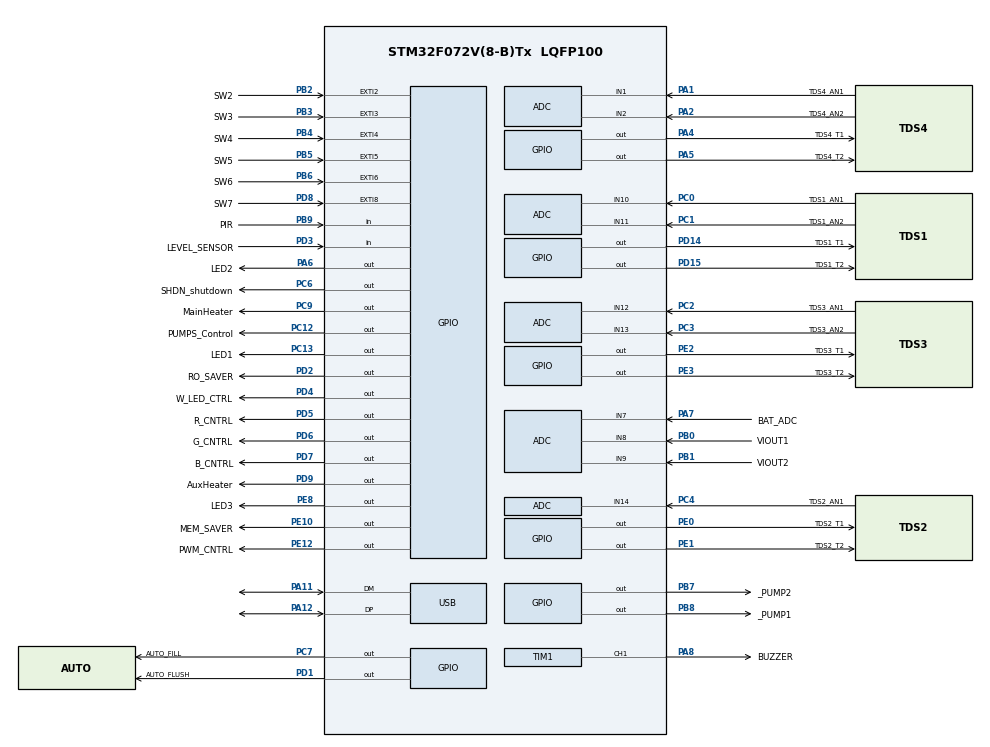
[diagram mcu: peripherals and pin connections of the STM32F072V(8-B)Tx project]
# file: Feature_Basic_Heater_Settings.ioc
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ADC.ContinuousConvMode=ENABLE
Mcu.Family=STM32F0
Mcu.Name=STM32F072V(8-B)Tx
Mcu.Package=LQFP100
NVIC.EXTI2_3_IRQn=true\:0\:0\:false\:false\:true\:true\:true\:true
NVIC.EXTI4_15_IRQn=true\:0\:0\:false\:false\:true\:true\:true\:true
NVIC.TIM1_BRK_UP_TRG_COM_IRQn=true\:0\:0\:false\:false\:true\:true\:true\:true
NVIC.TIM1_CC_IRQn=true\:0\:0\:false\:false\:true\:true\:true\:true
NVIC.TIM6_DAC_IRQn=true\:0\:0\:false\:false\:true\:true\:true\:true
NVIC.USB_IRQn=true\:0\:0\:false\:false\:true\:false\:true\:true
PA1.GPIO_Label=TDS4_AN1
PA1.Mode=IN1
PA1.Signal=ADC_IN1
PA11.Mode=Device
PA11.Signal=USB_DM
PA12.Mode=Device
PA12.Signal=USB_DP
PA2.GPIO_Label=TDS4_AN2
PA2.Mode=IN2
PA2.Signal=ADC_IN2
PA4.GPIO_Label=TDS4_T1
PA4.Signal=GPIO_Output
PA5.GPIO_Label=TDS4_T2
PA5.Signal=GPIO_Output
PA6.GPIO_Label=LED2
PA6.Signal=GPIO_Output
PA7.GPIO_Label=BAT_ADC
PA7.Mode=IN7
PA7.Signal=ADC_IN7
PA8.GPIO_Label=BUZZER
PA8.Signal=S_TIM1_CH1
PB0.GPIO_Label=VIOUT1
PB0.Mode=IN8
PB0.Signal=ADC_IN8
PB1.GPIO_Label=VIOUT2
PB1.Mode=IN9
PB1.Signal=ADC_IN9
PB2.GPIO_Label=SW2
PB2.GPIO_ModeDefaultEXTI=GPIO_MODE_IT_FALLING
PB2.Signal=GPXTI2
PB3.GPIO_Label=SW3
PB3.GPIO_ModeDefaultEXTI=GPIO_MODE_IT_FALLING
PB3.Signal=GPXTI3
PB4.GPIO_Label=SW4
PB4.GPIO_ModeDefaultEXTI=GPIO_MODE_IT_FALLING
PB4.Signal=GPXTI4
PB5.GPIO_Label=SW5
PB5.GPIO_ModeDefaultEXTI=GPIO_MODE_IT_FALLING
PB5.Signal=GPXTI5
PB6.GPIO_Label=SW6
PB6.GPIO_ModeDefaultEXTI=GPIO_MODE_IT_FALLING
PB6.Signal=GPXTI6
PB7.GPIO_Label=_PUMP2
PB7.Signal=GPIO_Output
PB8.GPIO_Label=_PUMP1
PB8.Signal=GPIO_Output
PB9.GPIO_Label=PIR
PB9.Signal=GPIO_Input
PC0.GPIO_Label=TDS1_AN1
PC0.Mode=IN10
PC0.Signal=ADC_IN10
PC1.GPIO_Label=TDS1_AN2
PC1.Mode=IN11
PC1.Signal=ADC_IN11
PC12.GPIO_Label=PUMPS_Control
PC12.Signal=GPIO_Output
PC13.GPIO_Label=LED1
PC13.Signal=GPIO_Output
PC2.GPIO_Label=TDS3_AN1
PC2.Mode=IN12
PC2.Signal=ADC_IN12
PC3.GPIO_Label=TDS3_AN2
PC3.Mode=IN13
PC3.Signal=ADC_IN13
PC4.GPIO_Label=TDS2_AN1
PC4.Mode=IN14
PC4.Signal=ADC_IN14
PC5.GPIO_Label=TDS2_AN2
PC5.Signal=ADC_IN15
PC6.GPIO_Label=SHDN_shutdown
PC6.Signal=GPIO_Output
PC7.GPIO_Label=AUTO_FILL
PC7.Signal=GPIO_Output
PC9.GPIO_Label=MainHeater
PC9.Signal=GPIO_Output
PD1.GPIO_Label=AUTO_FLUSH
PD1.Signal=GPIO_Output
PD14.GPIO_Label=TDS1_T1
PD14.Signal=GPIO_Output
PD15.GPIO_Label=TDS1_T2
PD15.Signal=GPIO_Output
PD2.GPIO_Label=RO_SAVER
PD2.Signal=GPIO_Output
PD3.GPIO_Label=LEVEL_SENSOR
PD3.GPIO_PuPd=GPIO_PULLUP
PD3.Signal=GPIO_Input
PD4.GPIO_Label=W_LED_CTRL
PD4.Signal=GPIO_Output
PD5.GPIO_Label=R_CNTRL
PD5.Signal=GPIO_Output
PD6.GPIO_Label=G_CNTRL
PD6.Signal=GPIO_Output
PD7.GPIO_Label=B_CNTRL
PD7.Signal=GPIO_Output
PD8.GPIO_Label=SW7
PD8.GPIO_ModeDefaultEXTI=GPIO_MODE_IT_FALLING
PD8.Signal=GPXTI8
PD9.GPIO_Label=AuxHeater
PD9.Signal=GPIO_Output
PE0.GPIO_Label=TDS2_T1
PE0.Signal=GPIO_Output
PE1.GPIO_Label=TDS2_T2
PE1.Signal=GPIO_Output
PE10.GPIO_Label=MEM_SAVER
PE10.Signal=GPIO_Output
PE12.GPIO_Label=PWM_CNTRL
PE12.Signal=GPIO_Output
PE2.GPIO_Label=TDS3_T1
PE2.Signal=GPIO_Output
PE3.GPIO_Label=TDS3_T2
PE3.Signal=GPIO_Output
PE8.GPIO_Label=LED3
PE8.Signal=GPIO_Output
PF0-OSC_IN.Mode=HSE-External-Oscillator
PF0-OSC_IN.Signal=RCC_OSC_IN
PF1-OSC_OUT.Mode=HSE-External-Oscillator
PF1-OSC_OUT.Signal=RCC_OSC_OUT
ProjectManager.HeapSize=0x200
ProjectManager.StackSize=0x400
ProjectManager.TargetToolchain=STM32CubeIDE
RCC.AHBFreq_Value=48000000
RCC.APB1Freq_Value=48000000
RCC.APB1TimFreq_Value=48000000
RCC.HCLKFreq_Value=48000000
RCC.SYSCLKFreq_VALUE=48000000
RCC.SYSCLKSource=RCC_SYSCLKSOURCE_HSI48
SH.S_TIM1_CH1.0=TIM1_CH1,PWM Generation1 CH1
TIM1.Channel-PWM\ Generation1\ CH1=TIM_CHANNEL_1
TIM1.Channel-PWM\ Generation2\ No\ Output=TIM_CHANNEL_2
TIM1.Channel-PWM\ Generation3\ No\ Output=TIM_CHANNEL_3
TIM1.Channel-PWM\ Generation4\ No\ Output=TIM_CHANNEL_4
TIM1.Period=1000-1
TIM1.Prescaler=48-1
TIM1.Pulse-PWM\ Generation1\ CH1=499
TIM6.Period=100
TIM6.Prescaler=48000
USB_DEVICE.CLASS_NAME_FS=CDC
USB_DEVICE.VirtualMode=Cdc
USB_DEVICE.VirtualModeFS=Cdc_FS
VP_TIM1_VS_ClockSourceINT.Mode=Internal
VP_TIM1_VS_no_output2.Mode=PWM Generation2 No Output
VP_TIM1_VS_no_output3.Mode=PWM Generation3 No Output
VP_TIM1_VS_no_output4.Mode=PWM Generation4 No Output
VP_TIM6_VS_ClockSourceINT.Mode=Enable_Timer
VP_USB_DEVICE_VS_USB_DEVICE_CDC_FS.Mode=CDC_FS
board=custom

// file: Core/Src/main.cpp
/* USER CODE BEGIN Header */
/**
  ******************************************************************************
  * @file           : main.c
  * @brief          : Main program body
  ******************************************************************************
  * @attention
  *
  * Copyright (c) 2024 STMicroelectronics.
  * All rights reserved.
  *
  * This software is licensed under terms that can be found in the LICENSE file
  * in the root directory of this software component.
  * If no LICENSE file comes with this software, it is provided AS-IS.
  *
  ******************************************************************************
  */
/* USER CODE END Header */
#include <mainApp.hpp>
#include "main.h"
#include "usb_device.h"
#include "_DEBUG_.h"

/* USER CODE BEGIN PD */
#define TIME 5*1000
/* USER CODE END PD */

TIM_HandleTypeDef htim1;
TIM_HandleTypeDef htim6;
ADC_HandleTypeDef hadc;

/* USER CODE BEGIN PV */
MainApp app;
/* USER CODE END PV */

extern "C" void SystemClock_Config(void);
static void MX_GPIO_Init(void);
static void MX_ADC_Init(void);
static void MX_TIM1_Init(void);
static void MX_TIM6_Init(void);
//static void MX_TIM17_Init(void);

int main(void)
{

  /* MCU Configuration--------------------------------------------------------*/

  /* Reset of all peripherals, Initializes the Flash interface and the Systick. */
  HAL_Init();

  /* Configure the system clock */
  SystemClock_Config();

  /* USER CODE BEGIN 2 */

  /* Initialize all configured peripherals */
  MX_GPIO_Init();
  MX_USB_DEVICE_Init();
  MX_ADC_Init();
  MX_TIM1_Init();
  MX_TIM6_Init();
//  MX_TIM17_Init();

  app.setup();
  /* USER CODE END 2 */

  /* Infinite loop */
  while (1)
  {

    /* USER CODE BEGIN 3 */
	  app.loop();
  }
  /* USER CODE END 3 */
}

extern "C" void SystemClock_Config(void)
{
  RCC_OscInitTypeDef RCC_OscInitStruct = {0};
  RCC_ClkInitTypeDef RCC_ClkInitStruct = {0};
  RCC_PeriphCLKInitTypeDef PeriphClkInit = {0};

  /** Initializes the RCC Oscillators according to the specified parameters
  * in the RCC_OscInitTypeDef structure.
  */
  RCC_OscInitStruct.OscillatorType = RCC_OSCILLATORTYPE_HSI14|RCC_OSCILLATORTYPE_HSI48;
  RCC_OscInitStruct.HSI48State = RCC_HSI48_ON;
  RCC_OscInitStruct.HSI14State = RCC_HSI14_ON;
  RCC_OscInitStruct.HSI14CalibrationValue = 16;
  RCC_OscInitStruct.PLL.PLLState = RCC_PLL_NONE;
  if (HAL_RCC_OscConfig(&RCC_OscInitStruct) != HAL_OK)
  {
    Error_Handler();
  }

  /** Initializes the CPU, AHB and APB buses clocks
  */
  RCC_ClkInitStruct.ClockType = RCC_CLOCKTYPE_HCLK|RCC_CLOCKTYPE_SYSCLK
                              |RCC_CLOCKTYPE_PCLK1;
  RCC_ClkInitStruct.SYSCLKSource = RCC_SYSCLKSOURCE_HSI48;
  RCC_ClkInitStruct.AHBCLKDivider = RCC_SYSCLK_DIV1;
  RCC_ClkInitStruct.APB1CLKDivider = RCC_HCLK_DIV1;

  if (HAL_RCC_ClockConfig(&RCC_ClkInitStruct, FLASH_LATENCY_1) != HAL_OK)
  {
    Error_Handler();
  }
  PeriphClkInit.PeriphClockSelection = RCC_PERIPHCLK_USB;
  PeriphClkInit.UsbClockSelection = RCC_USBCLKSOURCE_HSI48;

  if (HAL_RCCEx_PeriphCLKConfig(&PeriphClkInit) != HAL_OK)
  {
    Error_Handler();
  }
}

static void MX_ADC_Init(void)
{

  ADC_ChannelConfTypeDef sConfig = {0};

  /** Configure the global features of the ADC (Clock, Resolution, Data Alignment and number of conversion)
  */
  hadc.Instance = ADC1;
  hadc.Init.ClockPrescaler = ADC_CLOCK_ASYNC_DIV1;
  hadc.Init.Resolution = ADC_RESOLUTION_12B;
  hadc.Init.DataAlign = ADC_DATAALIGN_RIGHT;
  hadc.Init.ScanConvMode = ADC_SCAN_DIRECTION_FORWARD;
  hadc.Init.EOCSelection = ADC_EOC_SINGLE_CONV;
  hadc.Init.LowPowerAutoWait = DISABLE;
  hadc.Init.LowPowerAutoPowerOff = DISABLE;
  hadc.Init.ContinuousConvMode = ENABLE;
  hadc.Init.DiscontinuousConvMode = DISABLE;
  hadc.Init.ExternalTrigConv = ADC_SOFTWARE_START;
  hadc.Init.ExternalTrigConvEdge = ADC_EXTERNALTRIGCONVEDGE_NONE;
  hadc.Init.DMAContinuousRequests = DISABLE;
  hadc.Init.Overrun = ADC_OVR_DATA_PRESERVED;
  if (HAL_ADC_Init(&hadc) != HAL_OK)
  {
    Error_Handler();
  }

  /** Configure for the selected ADC regular channel to be converted.
  */
  sConfig.Channel = ADC_CHANNEL_1;
  sConfig.Rank = ADC_RANK_CHANNEL_NUMBER;
  sConfig.SamplingTime = ADC_SAMPLETIME_1CYCLE_5;
  if (HAL_ADC_ConfigChannel(&hadc, &sConfig) != HAL_OK)
  {
    Error_Handler();
  }

  /** Configure for the selected ADC regular channel to be converted.
  */
  sConfig.Channel = ADC_CHANNEL_2;
  if (HAL_ADC_ConfigChannel(&hadc, &sConfig) != HAL_OK)
  {
    Error_Handler();
  }

  /** Configure for the selected ADC regular channel to be converted.
  */
  sConfig.Channel = ADC_CHANNEL_7;
  if (HAL_ADC_ConfigChannel(&hadc, &sConfig) != HAL_OK)
  {
    Error_Handler();
  }

  /** Configure for the selected ADC regular channel to be converted.
  */
  sConfig.Channel = ADC_CHANNEL_8;
  if (HAL_ADC_ConfigChannel(&hadc, &sConfig) != HAL_OK)
  {
    Error_Handler();
  }

  /** Configure for the selected ADC regular channel to be converted.
  */
  sConfig.Channel = ADC_CHANNEL_9;
  if (HAL_ADC_ConfigChannel(&hadc, &sConfig) != HAL_OK)
  {
    Error_Handler();
  }

  /** Configure for the selected ADC regular channel to be converted.
  */
  sConfig.Channel = ADC_CHANNEL_10;
  if (HAL_ADC_ConfigChannel(&hadc, &sConfig) != HAL_OK)
  {
    Error_Handler();
  }

  /** Configure for the selected ADC regular channel to be converted.
  */
  sConfig.Channel = ADC_CHANNEL_11;
  if (HAL_ADC_ConfigChannel(&hadc, &sConfig) != HAL_OK)
  {
    Error_Handler();
  }

  /** Configure for the selected ADC regular channel to be converted.
  */
  sConfig.Channel = ADC_CHANNEL_12;
  if (HAL_ADC_ConfigChannel(&hadc, &sConfig) != HAL_OK)
  {
    Error_Handler();
  }

  /** Configure for the selected ADC regular channel to be converted.
  */
  sConfig.Channel = ADC_CHANNEL_13;
  if (HAL_ADC_ConfigChannel(&hadc, &sConfig) != HAL_OK)
  {
    Error_Handler();
  }

  /** Configure for the selected ADC regular channel to be converted.
  */
  sConfig.Channel = ADC_CHANNEL_14;
  if (HAL_ADC_ConfigChannel(&hadc, &sConfig) != HAL_OK)
  {
    Error_Handler();
  }

}

static void MX_TIM1_Init(void)
{

  TIM_ClockConfigTypeDef sClockSourceConfig = {0};
  TIM_MasterConfigTypeDef sMasterConfig = {0};
  TIM_OC_InitTypeDef sConfigOC = {0};
  TIM_BreakDeadTimeConfigTypeDef sBreakDeadTimeConfig = {0};

  htim1.Instance = TIM1;
  htim1.Init.Prescaler = 48-1;
  htim1.Init.CounterMode = TIM_COUNTERMODE_UP;
  htim1.Init.Period = 1000-1;
  htim1.Init.ClockDivision = TIM_CLOCKDIVISION_DIV1;
  htim1.Init.RepetitionCounter = 0;
  htim1.Init.AutoReloadPreload = TIM_AUTORELOAD_PRELOAD_DISABLE;
  if (HAL_TIM_Base_Init(&htim1) != HAL_OK)
  {
    Error_Handler();
  }
  sClockSourceConfig.ClockSource = TIM_CLOCKSOURCE_INTERNAL;
  if (HAL_TIM_ConfigClockSource(&htim1, &sClockSourceConfig) != HAL_OK)
  {
    Error_Handler();
  }
  if (HAL_TIM_PWM_Init(&htim1) != HAL_OK)
  {
    Error_Handler();
  }
  sMasterConfig.MasterOutputTrigger = TIM_TRGO_RESET;
  sMasterConfig.MasterSlaveMode = TIM_MASTERSLAVEMODE_DISABLE;
  if (HAL_TIMEx_MasterConfigSynchronization(&htim1, &sMasterConfig) != HAL_OK)
  {
    Error_Handler();
  }
  sConfigOC.OCMode = TIM_OCMODE_PWM1;
  sConfigOC.Pulse = 499;
  sConfigOC.OCPolarity = TIM_OCPOLARITY_HIGH;
  sConfigOC.OCNPolarity = TIM_OCNPOLARITY_HIGH;
  sConfigOC.OCFastMode = TIM_OCFAST_DISABLE;
  sConfigOC.OCIdleState = TIM_OCIDLESTATE_RESET;
  sConfigOC.OCNIdleState = TIM_OCNIDLESTATE_RESET;
  if (HAL_TIM_PWM_ConfigChannel(&htim1, &sConfigOC, TIM_CHANNEL_1) != HAL_OK)
  {
    Error_Handler();
  }
  sConfigOC.Pulse = 0;
  if (HAL_TIM_PWM_ConfigChannel(&htim1, &sConfigOC, TIM_CHANNEL_2) != HAL_OK)
  {
    Error_Handler();
  }
  if (HAL_TIM_PWM_ConfigChannel(&htim1, &sConfigOC, TIM_CHANNEL_3) != HAL_OK)
  {
    Error_Handler();
  }
  if (HAL_TIM_PWM_ConfigChannel(&htim1, &sConfigOC, TIM_CHANNEL_4) != HAL_OK)
  {
    Error_Handler();
  }
  sBreakDeadTimeConfig.OffStateRunMode = TIM_OSSR_DISABLE;
  sBreakDeadTimeConfig.OffStateIDLEMode = TIM_OSSI_DISABLE;
  sBreakDeadTimeConfig.LockLevel = TIM_LOCKLEVEL_OFF;
  sBreakDeadTimeConfig.DeadTime = 0;
  sBreakDeadTimeConfig.BreakState = TIM_BREAK_DISABLE;
  sBreakDeadTimeConfig.BreakPolarity = TIM_BREAKPOLARITY_HIGH;
  sBreakDeadTimeConfig.AutomaticOutput = TIM_AUTOMATICOUTPUT_DISABLE;
  if (HAL_TIMEx_ConfigBreakDeadTime(&htim1, &sBreakDeadTimeConfig) != HAL_OK)
  {
    Error_Handler();
  }
  HAL_TIM_MspPostInit(&htim1);

}

static void MX_TIM6_Init(void)
{

  TIM_MasterConfigTypeDef sMasterConfig = {0};

  htim6.Instance = TIM6;
  htim6.Init.Prescaler = 48000;
  htim6.Init.CounterMode = TIM_COUNTERMODE_UP;
  htim6.Init.Period = 100;
  htim6.Init.AutoReloadPreload = TIM_AUTORELOAD_PRELOAD_DISABLE;
  if (HAL_TIM_Base_Init(&htim6) != HAL_OK)
  {
    Error_Handler();
  }
  sMasterConfig.MasterOutputTrigger = TIM_TRGO_RESET;
  sMasterConfig.MasterSlaveMode = TIM_MASTERSLAVEMODE_DISABLE;
  if (HAL_TIMEx_MasterConfigSynchronization(&htim6, &sMasterConfig) != HAL_OK)
  {
    Error_Handler();
  }

}

static void MX_GPIO_Init(void)
{
  GPIO_InitTypeDef GPIO_InitStruct = {0};

  /* GPIO Ports Clock Enable */
  __HAL_RCC_GPIOC_CLK_ENABLE();
  __HAL_RCC_GPIOF_CLK_ENABLE();
  __HAL_RCC_GPIOA_CLK_ENABLE();
  __HAL_RCC_GPIOB_CLK_ENABLE();
  __HAL_RCC_GPIOE_CLK_ENABLE();
  __HAL_RCC_GPIOD_CLK_ENABLE();

  // /*Configure GPIO pin Output Level */
  // HAL_GPIO_WritePin(GPIOE, TDS3_T1_Pin|TDS3_T2_Pin|LED3_Pin|MEM_SAVER_Pin
  //                         |PWM_CNTRL_Pin|TDS2_T1_Pin|TDS2_T2_Pin, GPIO_PIN_RESET);

  // /*Configure GPIO pin Output Level */
  // HAL_GPIO_WritePin(GPIOC, LED1_Pin|SHDN_shutdown_Pin|AUTO_FILL_Pin|MainHeater_Pin
  //                         |PUMPS_Control_Pin, GPIO_PIN_RESET);

  // /*Configure GPIO pin Output Level */
  // HAL_GPIO_WritePin(GPIOA, TDS4_T1_Pin|TDS4_T2_Pin|LED2_Pin, GPIO_PIN_RESET);

  /*Configure GPIO pin Output Level */
  HAL_GPIO_WritePin(GPIOC, SHDN_shutdown_Pin|AUTO_FILL_Pin|MainHeater_Pin|PUMPS_Control_Pin, GPIO_PIN_RESET);
  HAL_GPIO_WritePin(GPIOC, LED1_Pin, GPIO_PIN_SET);

  /*Configure GPIO pin Output Level */
  HAL_GPIO_WritePin(LED2_GPIO_Port, LED2_Pin, GPIO_PIN_SET);

  /*Configure GPIO pin Output Level */
  HAL_GPIO_WritePin(GPIOE, MEM_SAVER_Pin|PWM_CNTRL_Pin, GPIO_PIN_RESET);
  HAL_GPIO_WritePin(GPIOE, LED3_Pin, GPIO_PIN_SET);

  /*Configure GPIO pin Output Level */
  HAL_GPIO_WritePin(GPIOD, AuxHeater_Pin|RO_SAVER_Pin|AUTO_FLUSH_Pin
                          |W_LED_CTRL_Pin|R_CNTRL_Pin|G_CNTRL_Pin|B_CNTRL_Pin, GPIO_PIN_RESET);

  /*Configure GPIO pin Output Level */
  HAL_GPIO_WritePin(GPIOB, _PUMP2_Pin|_PUMP1_Pin, GPIO_PIN_RESET);

  /*Configure GPIO pins : TDS3_T1_Pin TDS3_T2_Pin LED3_Pin MEM_SAVER_Pin
                           PWM_CNTRL_Pin TDS2_T1_Pin TDS2_T2_Pin */
  GPIO_InitStruct.Pin = TDS3_T1_Pin|TDS3_T2_Pin|LED3_Pin|MEM_SAVER_Pin
                          |PWM_CNTRL_Pin|TDS2_T1_Pin|TDS2_T2_Pin;
  GPIO_InitStruct.Mode = GPIO_MODE_OUTPUT_PP;
  GPIO_InitStruct.Pull = GPIO_NOPULL;
  GPIO_InitStruct.Speed = GPIO_SPEED_FREQ_LOW;
  HAL_GPIO_Init(GPIOE, &GPIO_InitStruct);

  /*Configure GPIO pins : LED1_Pin SHDN_shutdown_Pin AUTO_FILL_Pin MainHeater_Pin
                           PUMPS_Control_Pin */
  GPIO_InitStruct.Pin = LED1_Pin|SHDN_shutdown_Pin|AUTO_FILL_Pin|MainHeater_Pin
                          |PUMPS_Control_Pin;
  GPIO_InitStruct.Mode = GPIO_MODE_OUTPUT_PP;
  GPIO_InitStruct.Pull = GPIO_NOPULL;
  GPIO_InitStruct.Speed = GPIO_SPEED_FREQ_LOW;
  HAL_GPIO_Init(GPIOC, &GPIO_InitStruct);

  /*Configure GPIO pins : TDS4_T1_Pin TDS4_T2_Pin LED2_Pin */
  GPIO_InitStruct.Pin = TDS4_T1_Pin|TDS4_T2_Pin|LED2_Pin;
  GPIO_InitStruct.Mode = GPIO_MODE_OUTPUT_PP;
  GPIO_InitStruct.Pull = GPIO_NOPULL;
  GPIO_InitStruct.Speed = GPIO_SPEED_FREQ_LOW;
  HAL_GPIO_Init(GPIOA, &GPIO_InitStruct);

  /*Configure GPIO pins : SW2_Pin SW3_Pin SW4_Pin SW5_Pin
                           SW6_Pin */
  GPIO_InitStruct.Pin = SW2_Pin|SW3_Pin|SW4_Pin|SW5_Pin
                          |SW6_Pin;
  GPIO_InitStruct.Mode = GPIO_MODE_IT_FALLING;
  GPIO_InitStruct.Pull = GPIO_NOPULL;
  HAL_GPIO_Init(GPIOB, &GPIO_InitStruct);

  /*Configure GPIO pin : SW7_Pin */
  GPIO_InitStruct.Pin = SW7_Pin;
  GPIO_InitStruct.Mode = GPIO_MODE_IT_FALLING;
  GPIO_InitStruct.Pull = GPIO_NOPULL;
  HAL_GPIO_Init(SW7_GPIO_Port, &GPIO_InitStruct);

  /*Configure GPIO pins : AuxHeater_Pin TDS1_T1_Pin TDS1_T2_Pin RO_SAVER_Pin
                           W_LED_CTRL_Pin R_CNTRL_Pin G_CNTRL_Pin B_CNTRL_Pin */
  GPIO_InitStruct.Pin = AuxHeater_Pin|TDS1_T1_Pin|TDS1_T2_Pin|RO_SAVER_Pin|AUTO_FLUSH_Pin
                          |W_LED_CTRL_Pin|R_CNTRL_Pin|G_CNTRL_Pin|B_CNTRL_Pin;
  GPIO_InitStruct.Mode = GPIO_MODE_OUTPUT_PP;
  GPIO_InitStruct.Pull = GPIO_NOPULL;
  GPIO_InitStruct.Speed = GPIO_SPEED_FREQ_LOW;
  HAL_GPIO_Init(GPIOD, &GPIO_InitStruct);

  /*Configure GPIO pin : LEVEL_SENSOR_Pin */
  GPIO_InitStruct.Pin = LEVEL_SENSOR_Pin;
  GPIO_InitStruct.Mode = GPIO_MODE_INPUT;
  GPIO_InitStruct.Pull = GPIO_PULLUP;
  HAL_GPIO_Init(LEVEL_SENSOR_GPIO_Port, &GPIO_InitStruct);

  /*Configure GPIO pins : _PUMP2_Pin _PUMP1_Pin */
  GPIO_InitStruct.Pin = _PUMP2_Pin|_PUMP1_Pin;
  GPIO_InitStruct.Mode = GPIO_MODE_OUTPUT_PP;
  GPIO_InitStruct.Pull = GPIO_NOPULL;
  GPIO_InitStruct.Speed = GPIO_SPEED_FREQ_LOW;
  HAL_GPIO_Init(GPIOB, &GPIO_InitStruct);

  /*Configure GPIO pin : PIR_Pin */
  GPIO_InitStruct.Pin = PIR_Pin;
  GPIO_InitStruct.Mode = GPIO_MODE_INPUT;
  GPIO_InitStruct.Pull = GPIO_NOPULL;
  HAL_GPIO_Init(PIR_GPIO_Port, &GPIO_InitStruct);

  /* EXTI interrupt init*/
  HAL_NVIC_SetPriority(EXTI2_3_IRQn, 0, 0);
  HAL_NVIC_EnableIRQ(EXTI2_3_IRQn);

  HAL_NVIC_SetPriority(EXTI4_15_IRQn, 0, 0);
  HAL_NVIC_EnableIRQ(EXTI4_15_IRQn);

}

void Error_Handler(void)
{
  /* USER CODE BEGIN Error_Handler_Debug */
  /* User can add his own implementation to report the HAL error return state */
  __disable_irq();
  bool flag = true;
  while (1)
  {
	 while(flag){
		 DEBUG_RTT(LOG_ERROR, "Error occurred\nMCU HALTING");
		 flag = false;
	 }
  }
  /* USER CODE END Error_Handler_Debug */
}

//#ifdef  USE_FULL_ASSERT
///**
//  * @brief  Reports the name of the source file and the source line number
//  *         where the assert_param error has occurred.
//  * @param  file: pointer to the source file name
//  * @param  line: assert_param error line source number
//  * @retval None
//  */
//void assert_failed(uint8_t *file, uint32_t line)
//{
//  /* USER CODE BEGIN 6 */
//  /* User can add his own implementation to report the file name and line number,
//     ex: printf("Wrong parameters value: file %s on line %d\r\n", file, line) */
//
//  /* USER CODE END 6 */
//}
//#endif /* USE_FULL_ASSERT */
